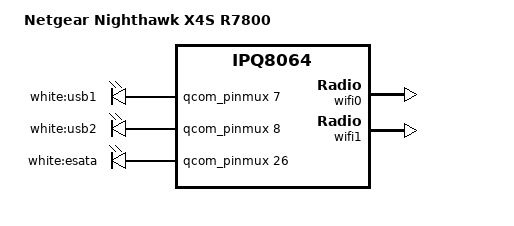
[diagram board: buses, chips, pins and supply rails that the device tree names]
#include "qcom-ipq8065-nighthawk.dtsi"

/ {
	model = "Netgear Nighthawk X4S R7800";
	compatible = "netgear,r7800", "qcom,ipq8065", "qcom,ipq8064";
};

&leds {
	usb1 {
		label = "white:usb1";
		gpios = <&qcom_pinmux 7 GPIO_ACTIVE_HIGH>;
	};

	usb2 {
		label = "white:usb2";
		gpios = <&qcom_pinmux 8 GPIO_ACTIVE_HIGH>;
	};

	esata {
		label = "white:esata";
		gpios = <&qcom_pinmux 26 GPIO_ACTIVE_HIGH>;
	};
};

&partitions {
	partition@1880000 {
		label = "ubi";
		reg = <0x1880000 0x6080000>;
	};

	partition@7900000 {
		label = "reserve";
		reg = <0x7900000 0x0700000>;
		read-only;
	};
};

/*
 * facboy: My DSA config that does not seem to work with NSS
 *
&mdio0 {
	status = "okay";

	pinctrl-0 = <&mdio0_pins>;
	pinctrl-names = "default";

	switch@16 {
		compatible = "qca,qca8337";
		#address-cells = <1>;
		#size-cells = <0>;

		reg = <0x16>;

		ports {
			#address-cells = <1>;
			#size-cells = <0>;
			port@0 {
				reg = <0>;
				label = "cpu";
				ethernet = <&gmac1>;
				phy-mode = "rgmii-id";

				fixed-link {
					speed = <1000>;
					full-duplex;
				};
			};

			port@1 {
				reg = <1>;
				label = "lan1";
			};

			port@2 {
				reg = <2>;
				label = "lan2";
			};

			port@3 {
				reg = <3>;
				label = "lan3";
			};

			port@4 {
				reg = <4>;
				label = "lan4";
			};

			port@5 {
				reg = <5>;
				label = "wan";
			};

FIXME			slash*
			 * Disabled until DSA supports multiple CPUs,
			 * otherwise it causes undefined behavior.
			 *
			port@6 {
				reg = <6>;
				label = "cpu";
				ethernet = <&gmac2>;
				phy-mode = "sgmii";

				fixed-link {
					speed = <1000>;
					full-duplex;
				};
			};
FIXME			*backslash
		};
	};
};
*/
&wifi0 {
	nvmem-cells = <&macaddr_art_6>;
	nvmem-cell-names = "mac-address";
	mac-address-increment = <(1)>;
};

&wifi1 {
	nvmem-cells = <&macaddr_art_6>;
	nvmem-cell-names = "mac-address";
	mac-address-increment = <(2)>;
};
